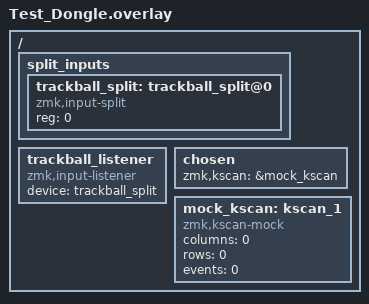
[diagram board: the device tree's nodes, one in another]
#include "Test.dtsi"
// #include "Test_trackball.dtsi"

/*input-split*/
/ {
    split_inputs {
        #address-cells = <1>;
        #size-cells = <0>;

        trackball_split: trackball_split@0 {
            compatible = "zmk,input-split";
            reg = <0>;
        };
    };

    trackball_listener: trackball_listener {
        compatible = "zmk,input-listener";
        status = "disabled";
        device = <&trackball_split>;
    };
};

/ {
    chosen {
        zmk,kscan = &mock_kscan;
    };
    mock_kscan: kscan_1 {
        compatible = "zmk,kscan-mock";
        columns = <0>;
        rows = <0>;
        events = <0>;
    };
};

// &xiao_serial { status = "disabled"; };

&trackball_listener {
    status = "okay";
};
